VERSION ""

NS_ :

BS_:

BU_: DLCM EPS ESC GWM RCU TCM

BO_ 82 ParkingBrake_0x052: 8 DLCM
 SG_ ParkingBrake : 2|1@0+ (1,0) [0|1] "" Vector__XXX

BO_ 128 EPS_SteeringAngle: 8 EPS
 SG_ SteeringAngle : 23|16@0+ (0.1,-2000.0) [-540|540] "deg" DLCM
 SG_ CRC8 : 63|8@0+ (1,0) [0|255] "" Vector__XXX

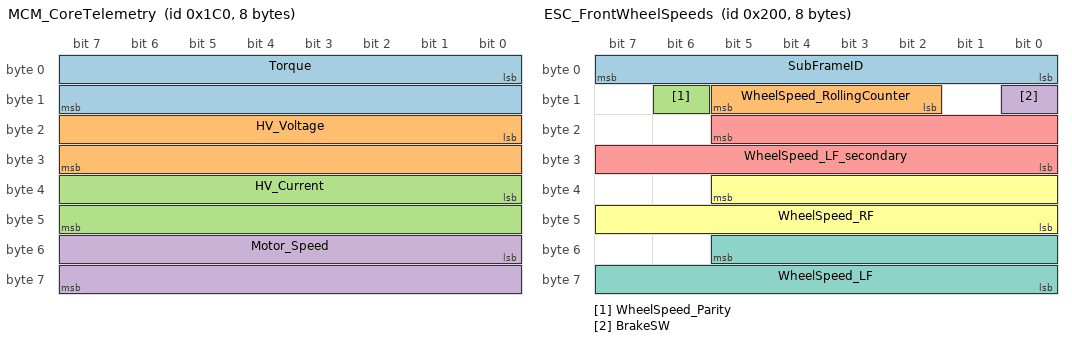
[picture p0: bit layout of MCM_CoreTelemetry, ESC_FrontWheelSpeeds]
BO_ 448 MCM_CoreTelemetry: 8 DLCM
 SG_ Torque      : 0|16@1+  (0.1,-3212.8)  [-500|500]     "Nm"  Vector__XXX
 SG_ HV_Voltage  : 16|16@1+ (0.1,-3212.8)  [0|500]        "V"   Vector__XXX
 SG_ HV_Current  : 32|16@1+ (0.1,-3212.8)  [-500|500]     "A"   Vector__XXX
 SG_ Motor_Speed : 48|16@1+ (0.5,-16064.0) [-12000|12000] "rpm" Vector__XXX

BO_ 512 ESC_FrontWheelSpeeds: 8 ESC
 SG_ SubFrameID              :  7|8@0+ (1,0)  [0|255]   "" Vector__XXX
 SG_ WheelSpeed_RollingCounter : 13|4@0+ (1,0)  [0|15]    "" DLCM
 SG_ WheelSpeed_Parity       : 14|1@0+ (1,0)  [0|1]     "" Vector__XXX
 SG_ BrakeSW                 :  8|1@0+ (1,0)  [0|1]     "" Vector__XXX
 SG_ WheelSpeed_LF_secondary : 21|14@0+ (1,0) [0|16383] "" DLCM
 SG_ WheelSpeed_RF           : 37|14@0+ (1,0) [0|16383] "" DLCM
 SG_ WheelSpeed_LF           : 53|14@0+ (1,0) [0|16383] "" Vector__XXX

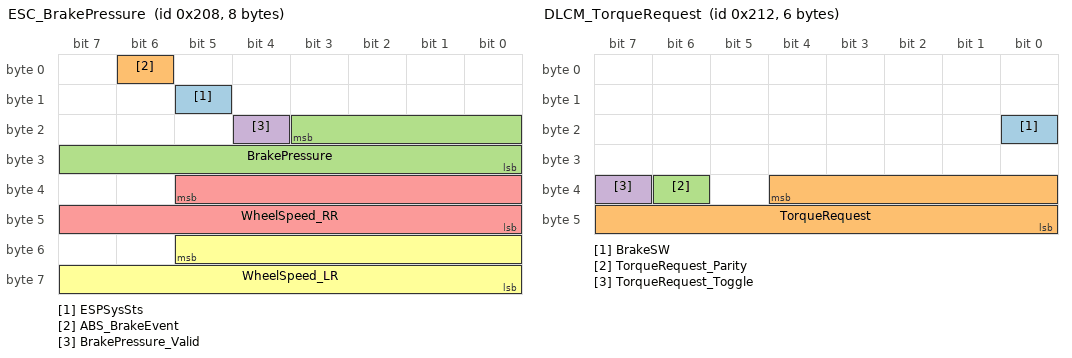
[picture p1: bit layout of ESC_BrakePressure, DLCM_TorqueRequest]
BO_ 520 ESC_BrakePressure: 8 ESC
 SG_ ESPSysSts : 13|1@0+ (1,0) [0|1] "" DLCM
 SG_ ABS_BrakeEvent : 6|1@0+ (1,0) [0|1] "" DLCM
 SG_ BrakePressure : 19|12@0+ (1,0) [0|4095] "" DLCM
 SG_ BrakePressure_Valid : 20|1@0+ (1,0) [0|1] "" DLCM
 SG_ WheelSpeed_RR : 37|14@0+ (1,0) [0|16383] "" Vector__XXX
 SG_ WheelSpeed_LR : 53|14@0+ (1,0) [0|16383] "" Vector__XXX

BO_ 528 VehicleMode_0x210: 6 DLCM
 SG_ ThottlePedalPos : 23|8@0+ (0.4,0) [0|99.6] "%" DLCM

BO_ 530 DLCM_TorqueRequest: 6 DLCM
 SG_ BrakeSW  : 16|1@0+ (1,0) [0|1]   "" Vector__XXX
 SG_ TorqueRequest : 36|13@0+ (0.25,-500) [-500|548.75] "Nm" Vector__XXX
 SG_ TorqueRequest_Parity : 38|1@0+ (1,0) [0|1] "" Vector__XXX
 SG_ TorqueRequest_Toggle : 39|1@0+ (1,0) [0|1] "" Vector__XXX

BO_ 533 misc_0x215: 7 Vector__XXX
 SG_ VehicleSpeed : 7|16@0+ (0.0078125,0) [0|511.9921875] "km/h" Vector__XXX

BO_ 576 SystemState_0x240: 8 Vector__XXX

BO_ 584 ExteriorLights_0x248: 8 Vector__XXX

BO_ 577 MCM_Thermal: 8 DLCM

BO_ 625 misc_0x271: 8 Vector__XXX

BO_ 632 DLCM_DriveKeepalive: 8 DLCM

BO_ 776 DLCM_ParkRequest: 5 DLCM
 SG_ ParkRequest     : 5|2@1+ (1,0) [0|3] "" TCM
 SG_ InputShaftSpeed : 8|16@1+ (0.5,-16064.0) [-12000|12000] "rpm" TCM

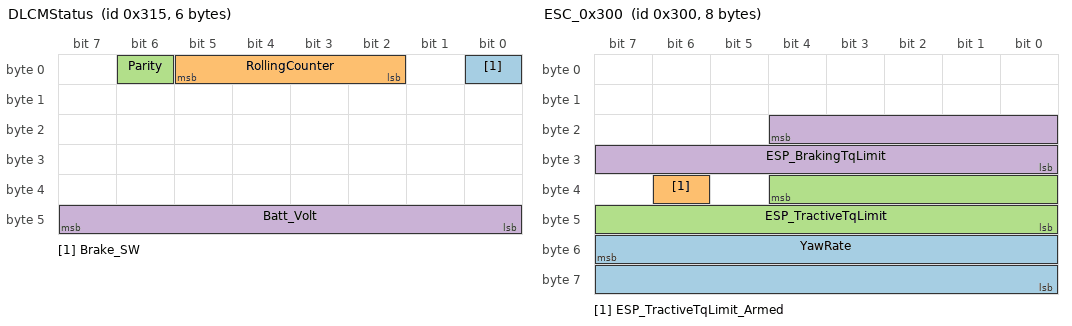
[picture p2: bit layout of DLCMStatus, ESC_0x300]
BO_ 789 DLCMStatus: 6 DLCM
 SG_ Brake_SW : 0|1@0+ (1,0) [0|1] "" Vector__XXX
 SG_ RollingCounter : 5|4@0+ (1,0) [0|15] "" Vector__XXX
 SG_ Parity : 6|1@0+ (1,0) [0|1] "" Vector__XXX
 SG_ Batt_Volt : 47|8@0+ (0.1,0) [0|25.5] "V" Vector__XXX

BO_ 805 DCANAnchor_0x325: 4 Vector__XXX

BO_ 768 ESC_0x300: 8 ESC
 SG_ YawRate : 55|16@0+ (0.0094,-308.2448) [-60|60] "deg/s" DLCM
 SG_ ESP_TractiveTqLimit_Armed : 38|1@0+ (1,0) [0|1] "" DLCM
 SG_ ESP_TractiveTqLimit : 36|13@0+ (2.5,-5000) [-5000|3237] "" DLCM
 SG_ ESP_BrakingTqLimit : 20|13@0+ (2.5,-5000) [-5000|3237] "" DLCM

BO_ 816 misc_0x330: 8 Vector__XXX
 SG_ Long_Accel : 63|8@0+ (0.08,-9.84) [-9.84|10.56] "m/s2" Vector__XXX

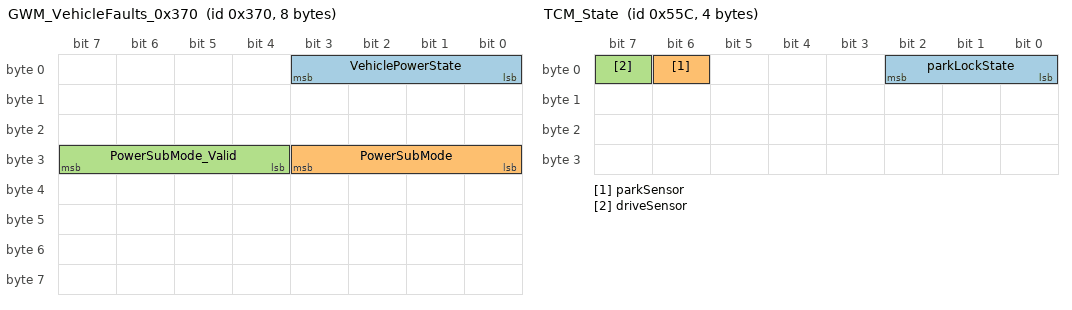
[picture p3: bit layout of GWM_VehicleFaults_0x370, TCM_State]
BO_ 880 GWM_VehicleFaults_0x370: 8 GWM
 SG_ VehiclePowerState  :  3|4@0+ (1,0) [0|15] "" Vector__XXX
 SG_ PowerSubMode       : 27|4@0+ (1,0) [0|15] "" Vector__XXX
 SG_ PowerSubMode_Valid : 31|4@0+ (1,0) [0|15] "" Vector__XXX

BO_ 1048 DLCM_Globals_0x418: 6 DLCM
 SG_ PRND : 7|8@0+ (1,0) [0|255] "" Vector__XXX
 SG_ GearStatus : 39|8@0+ (1,0) [0|255] "" Vector__XXX

BO_ 1372 TCM_State: 4 TCM
 SG_ parkLockState : 0|3@1+ (1,0) [0|6] "" DLCM
 SG_ parkSensor : 6|1@1+ (1,0) [0|1] "" Vector__XXX
 SG_ driveSensor : 7|1@1+ (1,0) [0|1] "" Vector__XXX

BO_ 1408 DCANAnchor_0x580: 4 Vector__XXX

BO_ 1536 misc_0x600: 8 RCU
 SG_ TPMS_TelltaleFault : 61|1@0+ (1,0) [0|1] "" Vector__XXX

BO_ 1786 GWM_VIN: 8 GWM
 SG_ VIN_Frame M  : 7|8@0+  (1,0) [0|2]    "" Vector__XXX
 SG_ VIN_C01  m0  : 15|8@0+ (1,0) [32|127] "" Vector__XXX
 SG_ VIN_C02  m0  : 23|8@0+ (1,0) [32|127] "" Vector__XXX
 SG_ VIN_C03  m0  : 31|8@0+ (1,0) [32|127] "" Vector__XXX
 SG_ VIN_C04  m0  : 39|8@0+ (1,0) [32|127] "" Vector__XXX
 SG_ VIN_C05  m0  : 47|8@0+ (1,0) [32|127] "" Vector__XXX
 SG_ VIN_C06  m0  : 55|8@0+ (1,0) [32|127] "" Vector__XXX
 SG_ VIN_C07  m0  : 63|8@0+ (1,0) [32|127] "" Vector__XXX
 SG_ VIN_C08  m1  : 15|8@0+ (1,0) [32|127] "" Vector__XXX
 SG_ VIN_C09  m1  : 23|8@0+ (1,0) [32|127] "" Vector__XXX
 SG_ VIN_C10  m1  : 31|8@0+ (1,0) [32|127] "" Vector__XXX
 SG_ VIN_C11  m1  : 39|8@0+ (1,0) [32|127] "" Vector__XXX
 SG_ VIN_C12  m1  : 47|8@0+ (1,0) [32|127] "" Vector__XXX
 SG_ VIN_C13  m1  : 55|8@0+ (1,0) [32|127] "" Vector__XXX
 SG_ VIN_C14  m1  : 63|8@0+ (1,0) [32|127] "" Vector__XXX
 SG_ VIN_C15  m2  : 15|8@0+ (1,0) [32|127] "" Vector__XXX
 SG_ VIN_C16  m2  : 23|8@0+ (1,0) [32|127] "" Vector__XXX
 SG_ VIN_C17  m2  : 31|8@0+ (1,0) [32|127] "" Vector__XXX

BO_ 81 misc_0x051: 8 Vector__XXX

BO_ 140 DLCM_0x08C: 1 DLCM
 SG_ Flag_B0bit2 : 2|1@0+ (1,0) [0|1] "" Vector__XXX

BO_ 360 Immobiliser_0x168: 8 Vector__XXX

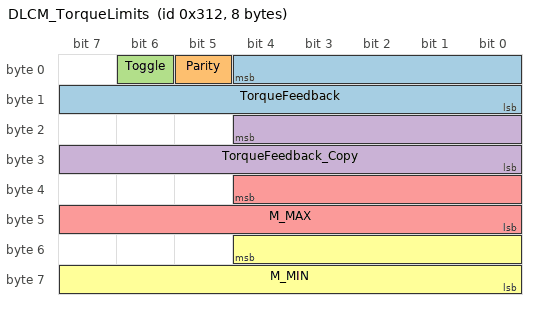
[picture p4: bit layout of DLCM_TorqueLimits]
BO_ 786 DLCM_TorqueLimits: 8 DLCM
 SG_ TorqueFeedback : 4|13@0+ (0.25,-500) [-500|548.75] "Nm" Vector__XXX
 SG_ Parity : 5|1@0+ (1,0) [0|1] "" Vector__XXX
 SG_ Toggle : 6|1@0+ (1,0) [0|1] "" Vector__XXX
 SG_ TorqueFeedback_Copy : 20|13@0+ (0.25,-500) [-500|548.75] "Nm" Vector__XXX
 SG_ M_MAX : 36|13@0+ (0.25,-500) [-500|548.75] "Nm" Vector__XXX
 SG_ M_MIN : 52|13@0+ (0.25,-500) [-500|548.75] "Nm" Vector__XXX

BO_ 1425 DLCM_ImmoVerdict: 7 DLCM
 SG_ Verdict : 7|8@0+ (1,0) [0|255] "" RCU

BO_ 1426 DLCM_ImmoChallenge: 8 DLCM

BO_ 1427 Immobiliser_0x593: 8 Vector__XXX

BO_ 1429 DLCM_0x595: 8 DLCM

BO_ 1539 RCU_ImmoCommand: 7 RCU
 SG_ Step : 7|8@0+ (1,0) [0|255] "" DLCM

BO_ 1556 RCU_ImmoResponse: 8 RCU

CM_ BO_ 82 "Parking brake. Transmitted by the DLCM: TX record 3 in the firmware's CAN configuration table at 0x80041B74, 50 ms period, matching the measured 20.0 Hz. Previously attributed to Vector__XXX. B0 carries six booleans ORed together by FUN_80080C14; only bit 2 (ParkingBrake) is identified.";
CM_ BO_ 128 "Steering angle sensor, factory name EPS SAM_1 (CODACAN), whose field list is Relative Steering angle, EPAS Failure, S/W Calibrated, S/W Sensor Type, Steering Msg Number, crcCheck. EPS transmits on D CAN; the gateway rebroadcasts it byte-exact onto B CAN. Byte map over 20.46 M frames (2026-09-27): B0, B1, B4 always 0x00; B5 0x80 except 38,066 frames at 0x90 (bit 4, meaning unknown, only ever set below 3.3 km/h); B6 message counter (steps +1 and +2); B7 CRC8-J1850. B5 bit 7 is set from the first frame after power-up in every capture, so no bit here marks a change to a calibrated or absolute angle; which bit carries which CODACAN field is not established. See notes/driver-inputs.md.";
CM_ SG_ 128 SteeringAngle "RELATIVE angle, zeroed at EPS power-up: raw 20000 is the wheel position when the EPS booted, NOT straight-ahead. It reads straight-ahead only if the wheel was straight at power-up; park with the wheel turned and straight-ahead reads 20000 minus that turn. Confirmed 2026-09-27 across 869 captures: all 12 EPS restarts resume with the B6 counter at 1 and raw exactly 20000, and the next drive's straight-ahead is predicted by 20000 - (angle at shutdown - previous straight-ahead) to within 5 deg in 96 % of 102 power cycles. Per-drive straight-ahead spans more than a full turn (raw ~14900..25500), and only ~12 % of drives fall within 2 deg of 20000, so a consumer needing straight-ahead must estimate it per power cycle. No re-zero while driving was found, and no absolute steering source is broadcast on any captured bus. The previous comment called 20000 the centre, measured as the corpus median; that median is a statistic of how the car is usually parked, not a property of the signal. STOPS: straight-ahead +/-5710 raw (+/-571 deg) wherever straight-ahead falls; corpus raw range 10281-31119, no saturation, no wrap, and 36 captures exceed the [-540|540] range declared here. SCALE 0.1 deg/count is the factory CODACAN scaling, not physically measured: a stationary lock-to-lock sweep spans 11,314 raw = 3.14 turns at that scale. The offset was -200.0 until 2026-09-20, which put 20000 at 1800 deg; notes/traction-control-analysis.md carried the same 10x error. See notes/driver-inputs.md, Relative angle, zeroed at EPS power-up.";
CM_ BO_ 448 "MCM telemetry forwarded by DLCM from private Motor CAN sub-bus. The M_CAN source is 0x209 (10 ms, 8 bytes, four little-endian uint16 accessors -- the same shape as this message), the MCM spec's AccurateFeedbacks. The DLCM has no COM transmit record for 0x1C0: it is relayed through a hardware mailbox, which is why earlier scans for a transmit site found nothing.";
CM_ SG_ 448 Torque "Regen shows negative values.";
CM_ SG_ 448 HV_Voltage "~335V at mid-SoC LFP pack.";
CM_ SG_ 448 HV_Current "Positive=discharge.";
CM_ SG_ 448 Motor_Speed "Positive=forward.";
CM_ BO_ 512 "ESC front wheel speed message, 200 Hz. NOT MULTIPLEXED -- the M/m0 declaration was removed 2026-09-27; see CM_ SG_ 512 SubFrameID for why and for the sub-frame values that actually occur. This sentence previously described the message as multiplexed and listed 0x0A/0x0B as startup frames, which contradicted both the new structure and the SG_ comment that had already withdrawn 0x0A/0x0B as C CAN values wrongly imported from the message sharing this ID on the other bus. Caught by a peer session, 2026-09-27. CONSUMER OBLIGATION CREATED BY THE DE-MUX: decode() now returns wheel speeds for EVERY sub-frame, including the 0x14 fault state and the 0x1C/0x1E init frames, from the same payload and with no indication that the frame is not a normal one. Before, a consumer that forgot to check SubFrameID got a DecodeError. That loud failure has been traded for a silent one. The trade is deliberate -- the old behaviour made the wheel-speed-fault car decode to SubFrameID alone for all 24,294 of its frames, which is indistinguishable from no data, and that is worse -- but it means EVERY consumer must now gate on SubFrameID itself rather than relying on cantools to refuse. Zero encoding 0xC000. Scale 0.0567 km/h per count (17.61 counts per km/h), equivalently 2.000 counts per wheel rpm -- the same encoding as 0x1C0 Motor_Speed and 0x308 InputShaftSpeed. Measured against 0x491 Primary_ODO, whose 0.1 km/count is verified across three Codas; see notes/artifacts/vehicle_speed_chain.py. CORRECTION 2026-09-24: the wheel speed channels are 14-bit, not 16-bit, and byte 1 is not an 8-bit counter. Layout read out of the DLCM firmware (TriCore image coda_dlcm_prog.bin): every received payload is fetched into a per-message RAM buffer and read only through the accessor band 0x800803FA-0x80080B4A, so the masks there are the module's own view of the field. See notes/dlcm/coda-dlcm-decompile-notes.md and notes/dlcm/artifacts/dlcm_signal_map.py. FUN_800805C2 reads B2 masked 0x3F with B3 and FUN_800805D8 reads B4 masked 0x3F with B5; bits 7-6 of B2, B4 and B6 are 0b11 in 196,707 of 196,707 m0 frames of frombonnydoon.log, which is exactly where the 'zero encoding 0xC000' above comes from -- those two bits are not magnitude. Narrowing the signals to 14 bits moves every decoded value down by 49152; the scale is unchanged. Byte 1 is BrakeSW at bit 0 (99.94 % agreement with 0x315 Brake_SW over 68,688 frames), a 4-bit rolling counter at bits 5-2 (+1 steps in 68,687 of 68,687), parity over (B1 & 0x3F) at bit 6 (68,688 of 68,688), and bits 7 and 1 always zero. The firmware reads only the counter nibble. The DLCM does not read B6-B7 (WheelSpeed_LF) at all.";
CM_ SG_ 512 SubFrameID "B0 sub-frame selector. REWRITTEN 2026-09-26. Values that actually occur on the ESC bus: 0x1E and 0x1C (a fixed startup pair), then 0x00 or 0x14 as the steady state, plus 0x20 in bursts. STARTUP: 0x1E for 1.91 s then 0x1C for 1.99 s, then steady state -- same durations to 10 ms and the same per-channel counts (192 and 200) on two different cars a year apart, so it is a fixed ESC init, not a fault. STEADY STATE selects by fault: a healthy car goes to 0x00, the wheel-speed-fault car goes to 0x14 and never emits 0x00 at all. 0x14 occurs in exactly one file corpus-wide. 0x20 CONFIRMED as a TC-event burst: 150 frames over 1.49 s per bus, appearing as ~300 corpus-wide because the gateway rebroadcast doubles it. Both channels carry it at identical timestamps. ESTABLISHED 2026-09-26 by a fixed-string scan of all 1,102 corpus files in both log roots (notes/artifacts/tpms_tc_event_exposure.py): a burst appears in 15 files / 15 distinct sessions, 16 bursts, 24.3 s of traction control across 221 days, and coda_20260422_102839_T0.log carries TWO bursts (99 s and 266 s in). So 'one block per capture' is NOT a rule and must not be relied on; the earlier 'NOT established' on this point is now answered. Bursts fall at scattered offsets (28 s to 1879 s into a file), so they are driving events and not an init artefact like the 0x1C/0x1E pair; under the 14-bit decode its speed fields are not empty but carry 144-146 distinct values with maxima around 600 against ~1700 for 0x00, so 'content unknown' understates it and the content is still unidentified. 0x0A/0x0B ARE WRONG and are withdrawn: a sweep of 1,082 corpus files found them only on the C CAN message that shares ID 0x200, never on the bus carrying 0x212. That other message has its own B0 spanning roughly 0x07-0x1B plus 0x9C, which also overlaps 0x1C and 0x1E in two files -- so split buses by CONTENT before histogramming B0 here, or you will re-import C CAN values into this comment as someone did in 2026-03. DECODING HAZARD: 0x1C and 0x1E are not declared multiplexer values, so cantools RAISES DecodeError on them ('expected multiplexer id 0, 10, 11, 20 or 32, but got 28' / '30') on every capture containing ESC startup; and because the wheel speeds are gated m0, the fault car decodes to SubFrameID alone with NO wheel speeds for all 24,294 of its frames, which is indistinguishable from no data. FIRMWARE: the DLCM does NOT gate on this byte. It copies every 0x200 frame into one buffer and reads the wheel-speed fields unconditionally; the only part of B0 read anywhere is bit 2 (FUN_800805EE), which feeds a status boolean and the safety monitor, not a demux. So the firmware CANNOT corroborate '0x14 has the same layout as 0x00' -- it never looks, and its silence must not be read as confirmation. That claim rests on log data alone. STARTUP POSITION, 2026-09-27: the 0x1E/0x1C pair marks a key-on, so it appears wherever in a capture the key-on falls -- including mid-capture when the key is cycled -- and its position in the file says nothing about the file. Confirmed by 23 mid-capture key cycles across 19 captures, each dated independently by 0x370 VehiclePowerState; see notes/key-cycle-detection.md. MULTIPLEXER REMOVED 2026-09-27. SubFrameID was declared M with every other signal gated m0. That was wrong in three ways and actively destructive: 0x1C and 0x1E were not declared mux values so cantools raised DecodeError on every capture containing ESC startup; the wheel-speed-fault car emits 0x14 for all 24,294 of its frames and so decoded to SubFrameID alone with NO wheel speeds, which is indistinguishable from no data; and the DLCM itself does not demux, as described above. All signals are now ungated. Verified on coda_20260322_153141_T0: 28,817 frames at 0x00, 200 at 0x1C and 192 at 0x1E all decode, all carrying wheel speeds, zero errors. B0 BIT 2 IS NOT AN INDEPENDENT BIT and is deliberately not declared as a signal: across the full observed value set it is set for 0x14, 0x1C and 0x1E and clear for 0x00 and 0x20, i.e. it is a function of SubFrameID meaning 'not a plain wheel-speed frame', covering both the fault steady state and the two init values. It is the only part of this byte the firmware reads. VAL_ CORRECTED 2026-09-27: 10 'Startup_0x0A' and 11 'Startup_0x0B' removed -- they were withdrawn in the prose above as C CAN values wrongly imported here, but had been left in the value table, which contradicted the comment. 0x1C and 0x1E added. See notes/artifacts/handoff_0x200_subframeid.md and notes/dlcm/coda-dlcm-decompile-notes.md.";
CM_ SG_ 512 WheelSpeed_RollingCounter "B1 rolling counter 0-125, valid only in SubFrameID=0x00 sub-frames.";
CM_ SG_ 512 WheelSpeed_LF "Zero=0xC000. Valid only in SubFrameID=0x00. Outer wheel in right turns. Spikes during FWD TC events. Scale 0.0567 km/h per count (17.61 counts per km/h), equivalently 2.000 counts per wheel rpm -- the same encoding as 0x1C0 Motor_Speed and 0x308 InputShaftSpeed. Measured against 0x491 Primary_ODO, whose 0.1 km/count is verified across three Codas; see notes/artifacts/vehicle_speed_chain.py. LOW-SPEED FLOOR (measured 2026-10-15, notes/dlcm/artifacts/chock_impact_check.py phases 2-3): this field reads 0 below ~15.5 wheel rpm, twice the 8.0 rpm floor of WheelSpeed_LF_secondary, RF, LR and RR; no non-zero value below 15.5 rpm occurs. LF_secondary, the same physical sensor, keeps the 8.0 rpm floor, so the difference is in how the ESC fills this field, not in the sensor. At all 395 braked stops sampled on this car this field was the first wheel to read 0, 0.18 / 0.28 / 0.57 s (p10 / p50 / p90) before the next. The parts car shows the same split (codapartscarlog.log). Consequence: an early zero here is NOT evidence of an impact or lock-up; use WheelSpeed_LF_secondary for low-speed work, and see its comment on the naming.";
CM_ SG_ 512 WheelSpeed_RF "Zero=0xC000. Valid only in SubFrameID=0x00. Inner wheel in right turns. Spikes during FWD TC events. Scale 0.0567 km/h per count (17.61 counts per km/h), equivalently 2.000 counts per wheel rpm -- the same encoding as 0x1C0 Motor_Speed and 0x308 InputShaftSpeed. Measured against 0x491 Primary_ODO, whose 0.1 km/count is verified across three Codas; see notes/artifacts/vehicle_speed_chain.py.";
CM_ SG_ 512 WheelSpeed_LF_secondary "Same physical sensor as WheelSpeed_LF (B6-B7), but NOT identical to it -- 'identical' corrected 2026-09-26. Measured on frombonnydoon, SubFrameID=0, n~196,700 per channel: byte-identical on only 45.7 % of frames, standard deviation of the difference 1.9 counts, and 3.81 % differ by more than 2. 'Same physical sensor' survives easily -- 1.9 counts against a signal spanning more than 1000, with near-zero mean offset. A whole-frame lag is excluded: same-frame matching (45.7 %) beats both one-frame shifts (22.1 % and 28.7 %). The disagreement is flat in speed (correlation +0.08, invariant) and positive against acceleration under every derivative estimator tried, but the magnitude is estimator-dependent and should not be quoted as a point value. Below 50 counts the channels agree 92.8 % of the time, with a heavy tail. Both channels give identical statistics on either bus, which also establishes that the gateway rebroadcast of 0x200 is byte-exact. DESPITE THE NAME, this is the left-front channel to prefer (2026-10-15): the DLCM reads this field and B4-B5 RF, not B6-B7 WheelSpeed_LF (coda-dlcm-decompile-notes.md), and its zero-speed floor is 8.0 wheel rpm like RF, LR and RR on this car and the parts car, where WheelSpeed_LF's is 15.5 rpm (notes/dlcm/artifacts/chock_impact_check.py phase 3). The primary/secondary labels date from traction-control-analysis.md (2026-03) and rest on no evidence; they are kept so InfluxDB field names and existing scripts do not change.";
CM_ BO_ 520 "ESC module. B4-B5=WheelSpeed_RR, B6-B7=WheelSpeed_LR (corrected from prior FL/FR hypothesis). CORRECTION 2026-09-24: BrakePressure is a 12-bit value with a separate validity bit, not a 16-bit field. Layout read out of the DLCM firmware (TriCore image coda_dlcm_prog.bin): every received payload is fetched into a per-message RAM buffer and read only through the accessor band 0x800803FA-0x80080B4A, so the masks there are the module's own view of the field. See notes/dlcm/coda-dlcm-decompile-notes.md and notes/dlcm/artifacts/dlcm_signal_map.py. FUN_8008062E computes ((B2 << 8) & 0xF00) | B3 and FUN_8008061C returns (B2 & 0x10) >> 4; both are called from the same two consumers, so no code in the image reads the magnitude without the flag. The old (1,-4096) offset happened to give the right number only because bit 12 IS the validity bit and is set whenever the signal is valid; invalid frames decoded as -1. B2 bits 7-5 are never set in any frame. The rear wheel speeds are narrowed to 14 bits on the same basis as 0x200, but by wire evidence only (B4 and B6 bits 7-6 are 0b11 in 197,248 of 197,248 frames) -- the DLCM does not read them, so there is no firmware confirmation. The firmware DOES read B0 bit 6, which no signal here covers; and it does NOT read ESPSysSts, which is set in 197,078 of those frames. **B0 BIT 6 IDENTIFIED 2026-10-03: it is the ABS BRAKE EVENT line, named by the DLCM's own DTC table.** Accessor FUN_8008060E (a0-0x1060 & 0x40 >> 6) -> FUN_8006ED3C, which stores a raw copy at a0-0x27d8 and a validity-qualified copy at 0xD000682E, and runs a rationality counter against CAL 0xA00212BE = 6000 feeding DEM event 124 = U2111 'Invalid Anti Lock Braking System Brake Event' (the neighbouring bit via FUN_800805EE feeds event 123 = U2110 'Invalid Anti-Lock Braking System Lamp Request'). The 'is 0 in every frame observed' clause above was true of the captures then to hand and is now known to be a property of the population, not of the signal: it asserts for 98 frames / 0.97 s in coda_20261002_175334 at t=424.02, 40 ms after a front-wheel slip and 40 ms before a full regen cut, and is 0 across 650,000+ frames of six other sessions. Its one consumer in the image is FUN_800764F6, which forces that function's output to zero when this bit and the commanded brake-lamp state 0xD0006831 are both set. See notes/dlcm/esp-torque-intervention.md.";
CM_ SG_ 520 BrakePressure "Engages ~40ms after brake switch.";
CM_ SG_ 520 ESPSysSts "B1 bit 5. Active (0x20) when ESC on, 0x00 at key-off.";
CM_ SG_ 520 WheelSpeed_RR "Zero=0xC000. Non-driven axle (does not spike during FWD TC events). C102B DTC 'Right Rear Wheel Speed Sensor Circuit' -- parts car confirms by stuck-at-0xFFFF fault sentinel. Scale 0.0567 km/h per count (17.61 counts per km/h), equivalently 2.000 counts per wheel rpm -- the same encoding as 0x1C0 Motor_Speed and 0x308 InputShaftSpeed. Measured against 0x491 Primary_ODO, whose 0.1 km/count is verified across three Codas; see notes/artifacts/vehicle_speed_chain.py.";
CM_ SG_ 520 WheelSpeed_LR "Zero=0xC000. Non-driven axle. Tracks vehicle reference speed. Scale 0.0567 km/h per count (17.61 counts per km/h), equivalently 2.000 counts per wheel rpm -- the same encoding as 0x1C0 Motor_Speed and 0x308 InputShaftSpeed. Measured against 0x491 Primary_ODO, whose 0.1 km/count is verified across three Codas; see notes/artifacts/vehicle_speed_chain.py.";
CM_ BO_ 528 "Vehicle mode / throttle. 50 Hz. Transmitted by the DLCM: TX record 7, 20 ms period. Previously attributed to Vector__XXX. Firmware also writes B3 bit 7 (parity over B2) and B4 bit 7 (alternating toggle), neither yet declared as a signal.";
CM_ BO_ 530 "DLCM Torque Request message (NOT steering angle -- VICD originally tagged EPS_SAM_1). 50 Hz. CORRECTION 2026-09-24: it is NOT two alternating sub-frames at 25 Hz. There is one TX record and one signal record; B2 bit 3 and B4 bit 7 are alternating toggle bits (50.00 % over 98,597 frames) and B2 bit 2 and B4 bit 6 are parity bits (both 100.00 % against the firmware expressions), which is what the B2 = 0x0C / 0x00 pattern was. Nothing is multiplexed and TorqueRequest is present in every frame. Layout read out of the DLCM firmware (TriCore image coda_dlcm_prog.bin): every received payload is fetched into a per-message RAM buffer and read only through the accessor band 0x800803FA-0x80080B4A, so the masks there are the module's own view of the field. See notes/dlcm/coda-dlcm-decompile-notes.md and notes/dlcm/artifacts/dlcm_signal_map.py. FUN_80080C14 writes the torque at B4 masked 0x1F with B5 from 0xD00069D2, the same variable DID 8539 reads; the encoding is raw = internal * 0.4 + 2000 with internal in 0.1 Nm, i.e. 0.25 Nm/count with zero at 2000. B4 bit 5 is always 1. B2 bits 1-0 come from the same firmware variable as 0x315 B0 bits 1-0.";
CM_ SG_ 530 BrakeSW "Triple-redundancy: same signal at 0x315 B0.bit0 and 0x200 B1.bit0. Confirmed 2026-09-24. The 0x212 and 0x315 copies are not independent -- FUN_80080C14 writes both from one variable (DAT_d00069E0 & 3). 0x200 is an ESC transmission and is the genuinely independent third copy: its B1 bit 0 agrees with 0x315 Brake_SW in 68,648 of 68,688 frames (99.94 %), the mismatches being single-frame edges.";
CM_ BO_ 533 "VICD: misc_Recvd 0x215. B0:B1 = VehicleSpeed (2026-10-26). B2:B3 and B4:B5 track each other while moving but are not wheel speeds; B6 has 4 values; all undecoded. Transmitter not shown: the DLCM receives it; the content is derived from the ESC wheel speeds, so the ESC is suspected. The TCM.ParkLock candidate was invalidated 2026-09-24. DLC corrected 2026-09-24 from 2 to 7: the DLCM's RX record declares 7 and the wire shows DLC 7.";
CM_ SG_ 533 VehicleSpeed "B0:B1 big-endian, km/h x 128. Confirmed 2026-10-26: integrated over time it reproduces the 0x491 odometer distance on four drives (ratio 0.991-1.006), and it correlates r = 1.000 with each ESC wheel speed (0x200/0x208) at a constant ratio. Zero whenever stationary. The HVAC reads it with a precedence bug. See notes/hvac/coda-hvac-decompile-notes.md section 5.4.";
CM_ BO_ 576 "System power mode. B0: 0x11=key-on (HV off), 0x01=Ready (HV on). Medium confidence. D+B CAN (gateway rebroadcast). DLC unconfirmed. See notes/driver-inputs.md.";
CM_ BO_ 584 "Exterior lights state. B1.bit3=any exterior lights on (boolean). B6=possible instrument dimming (unconfirmed). Medium confidence. D+B CAN (gateway rebroadcast). DLC unconfirmed. See notes/driver-inputs.md.";
CM_ BO_ 577 "MCM motor thermal data relayed by DLCM from private Motor CAN sub-bus. Carries Rotor temp, Stator temp, IGBT temp per CODACAN DLCM tab. Encoding: probable offset -40 degC, per-byte assignment unconfirmed. NOTE: 8 bytes seen in log data -- DLC may be higher than 3, verify before use. The M_CAN source is 0x20E (100 ms, exactly three byte-wide accessors in the firmware, matching the rotor/stator/IGBT triple), the MCM spec's Temperature message. Like 0x1C0 this is relayed through a hardware mailbox with no COM transmit record.";
CM_ BO_ 625 "VICD: misc_Recvd 0x271. Death Counter partial (integer bytes).";
CM_ BO_ 632 "DLCM Drive Keepalive. Carries KeepWakeNetworkDLCM and EngineStsRun per CODACAN. B1 bit 6 (mask 0x40) = HV/Drive Ready flag (medium confidence). Signal byte positions unconfirmed. DLC corrected 2026-09-24 from 2 to 8: the DLCM's TX record declares 8 and the wire shows DLC 8. Firmware writes only B0 and B1 bit 6, which matches the HV/Drive Ready note above.";
CM_ BO_ 776 "Park request from the DLCM to the BorgWarner TCM, plus the shaft speed the DLCM sends it. 10 ms, D CAN exclusive. B3-B4=constant 0x00. InputShaftSpeed uses the same encoding as Motor_Speed (0x1C0 B6-B7). CORRECTED 2026-09-24 -- this is NOT a TCM broadcast and B0 is NOT a pin-state report. It is TX record 9 in the DLCM's own CAN transmit table at 0x80041B74 with a 10 ms period, matching the measured 99.7 Hz, and FUN_80080C14 assembles all five bytes, taking B1-B2 from 0xD00069CA. ADDED 2026-10-06: 0xD00069CA = 0xD0005114 + 0x7D80, written by FUN_80074780 (search limited to the exported function set). The Vtrux EPRI DBC independently calls the same id the HCU park request command. Direction settled from data on both vehicles: the B0 change LEADS the TCM's own 0x55C parkLockState in both directions -- Coda +76, +89, +88, +85 ms over two P-R-N-D-N-R-P cycles; Vtrux +55 and +65 ms -- which a pin-state report cannot do on park ENGAGE. The 55-65 ms figures already recorded in notes/borgwarner.md as solenoid actuation delay are that command-to-acknowledge latency. The TCM's own state feedback is 0x55C. See notes/borgwarner.md.";
CM_ SG_ 776 ParkRequest "Byte 0 bits 6-5, a 2-bit command: 0=OFF, 1=Park, 2=UnPark. Bit spec and value table taken verbatim from the Vtrux EPRI DBC (SG_ ParkRequest : 5|2@1+ in epri-pt-bus.dbc, decoded from the vendor logging app), and matched exactly by the Coda firmware, which ORs DAT_d0006AF1 * 0x20 & 0x60 into this byte. Was declared as an 8-bit ParkPinState with 32=Park / 64=NotPark; those are the same two values seen as a 2-bit field (0x20 = 1, 0x40 = 2), but the third state 0 = OFF was missing and no bit outside 6-5 is ever set (0 frames of 3,855 on Coda, 0 of 6,423 on Vtrux).";
CM_ SG_ 776 InputShaftSpeed "Zero=0x7D80. Input shaft (not output): ratio to motor RPM = 2.000 on both Vtrux and Coda regardless of gear ratio.";
CM_ BO_ 789 "DLCM status. B1,B3 zero when stationary. CORRECTION 2026-09-24: B0 bits 7-2 are NOT a 6-bit rolling counter. Layout read out of the DLCM firmware (TriCore image coda_dlcm_prog.bin): every received payload is fetched into a per-message RAM buffer and read only through the accessor band 0x800803FA-0x80080B4A, so the masks there are the module's own view of the field. See notes/dlcm/coda-dlcm-decompile-notes.md and notes/dlcm/artifacts/dlcm_signal_map.py. FUN_80080C14 writes the counter as DAT_d0007F7E * 4 & 0x3C -- four bits at 5-2 -- and puts parity over (B0 & 0x3F) at bit 6. Measured on 98,597 frames: bits 5-2 advance by +1 in 98,596 of 98,596 steps (100.00 %), the old 6-bit reading only 31.27 %, and the parity holds in 98,597 of 98,597. Bit 7 and bit 1 are always zero; bit 0 is Brake_SW. This is the same defect shape as 0x200 byte 1.";
CM_ SG_ 789 Brake_SW "Engages ~40ms before hydraulic pressure.";
CM_ SG_ 789 Batt_Volt "Cross-check vs DCDC 14VMonitor (0x1D5).";
CM_ BO_ 805 "D CAN exclusive anchor ID. Never rebroadcast to B CAN. Signal content unknown.";
CM_ BO_ 816 "Longitudinal accelerometer, 50 Hz. DLC is 8, not the 1 previously recorded here: B0-B6 are constant (FC FC FC FD FF FF FF) and only B7 carries the signal. The earlier note read B0 as the accelerometer, which is a dead constant of -4. Confirmed 2026-09-20 against wheel-speed-derived acceleration over four drives.";
CM_ SG_ 816 Long_Accel "B7, offset binary with zero at raw 123 (the modal value over a whole drive; a regression against kinematic acceleration puts it at 122.6). Scale 0.08 m/s2/count is from VICD and is corroborated to about +/-12 % by the regression slope across drives, so treat the SCALE as approximate and the zero and the role as confirmed. Raw >= 200 is invalid (about 13 samples per drive) and should be discarded. Correlation against acceleration derived from 0x208 WheelSpeed_LR: r = 0.83-0.89 raw, rising to 0.88-0.93 once road grade is removed with a 30 s high-pass. The residual is dominated by noise in the wheel-speed derivative, not by this signal -- r rises monotonically as the derivative window widens, and is flat across +/-200 ms of lag. Independent physical check: integrating the recovered grade term gives -177 m over the frombonnydoon mountain descent and +6 m / +9 m over flat urban drives, with gradients of +/-9 % and +/-4 % respectively.";
CM_ BO_ 880 "GWM Vehicle Faults. Sender CONFIRMED as the GWM by the factory diagnostic manual: DTC master list row 215, U0146 \"COM Timeout with GWM (Vehicle Faults - 0x370)\" set by the BMU -- the same naming convention as row 214, U0108 \"COM Timeout with CHM (0x615)\", where the named module is the sender. Previously misc_0x370, sender Vector__XXX. VICD called it the Death Counter batch; the DLCM reads seven fields from it into its DTC evaluation block FUN_80074478, so both readings can hold in 8 bytes. ORIGINATES ON B CAN, not D CAN: in codadriveslowturnonwithdefroster2.log and DCDCRUNNingwithoutkeyon-then-key-on.log it is present from +0.01 s with D CAN asleep and reaches D CAN only when D CAN wakes (+9.46 s / +41.88 s); 2836 frames on B against 742 on D. The two copies are NOT identical -- B1 differs in 100 % of 34,919 matched pairs and looks like a bus tag (0x02 on D, 0x06 on B); every other byte including B0 matches exactly, which is what makes B0 usable as a bus-independent witness. The influx_upload coda profile excluded this on b_can until 2026-09-26, which kept the gateway copy and dropped the original; corrected to d_can. FILTER QUERIES TO bus='b_can'. After the 2026-09-27 rebuild InfluxDB holds 281,313 0x370 points on b_can carrying the full state ladder 0,1,2,3,4,5,6,9, plus 19 points spread across c_can, ch1 and ch2 that read only 0 and 1. Those 19 are not this message -- 0x370 is not in the C CAN native set listed in projects/coda/README.md -- and they decode to a spurious 'off'. The contamination is 0.007 % and sits entirely at the off end, so it will not move an aggregate, but a query looking for key-off events without a bus filter will find 19 fictitious ones. Not excluded in the upload profile because doing so costs a full corpus re-upload for 19 points; revisit if 0x370 is ever excluded for another reason. Fields read by the firmware: B0[3:0], B0[6:4], B1 bit 0, B1 bit 1, B1[3:2], B3[3:0], B3[7:4]. B1 and B0[6:4] are not yet declared as signals. Layout read out of the DLCM firmware (TriCore image coda_dlcm_prog.bin): every received payload is fetched into a per-message RAM buffer and read only through the accessor band 0x800803FA-0x80080B4A, so the masks there are the module's own view of the field. VICD additionally described it as a Death Counter batch using 6 bytes (B0-B4, B7) at 0.1 scale; those counters are not decoded here. See notes/dlcm/coda-dlcm-decompile-notes.md, notes/dlcm/artifacts/dlcm_signal_map.py and notes/key-cycle-detection.md.";
CM_ SG_ 880 VehiclePowerState "Vehicle power-state enumeration, and the only key-state indicator found so far that SURVIVES a key-off -- the GWM stays powered, so this dates an ignition cycle from outside it. 0x240 cannot: it reads 0x01 in 11,670 of 11,672 frames and dies with the key. FIELD BOUNDARY CONFIRMED: the DLCM reads B0 masked 0x0F (FUN_80080666) as its own field, and B0's high nibble is a constant 0x1 across 15,000 frames. VALUE NAMES ARE INFERRED from position in the ladder, not documented: the sequence 2 -> 4 -> 9 -> 6 -> 5 on the way up and 5 -> 3 -> 1 on the way down was read off codadriveslowturnonwithdefroster2.log, a deliberate slow key-on, and matches the key positions recorded independently in notes/driving-sequence-investigation.md (2026-02-19) to 0.04 s. The same ladder appears in 23 mid-capture key cycles across 19 captures corpus-wide. NOT the spec's Powermode signal despite covering the same state set: the DLCM functional requirements compare Powermode ordinally (< Ignition_On, < Ready) and these codes are not ordered -- Crank is 9, Ready is 5. Treat it as a coded enum over the Powermode states. A genuine key-off always shows the descent BEFORE the GWM stops; the same value either side of a silence with no descent means the capture lost the bus, not that the key moved. READ THE B CAN COPY FOR A KEY-OFF, NOT THIS ONE (established 2026-09-27 with a peer session, and it corrects the dwell figures first written here). The GWM stops rebroadcasting 0x370 onto D CAN about 6 s into the off period while still transmitting it on B CAN: measured B-minus-D survival of 6.2, 6.2, 6.2 and 6.1 s across four captures. So the D CAN copy TRUNCATES the descent -- it typically ends mid-state-1 and never reaches the terminal state 0 at all, which is why state 0 was initially missed and why state 1 looked like a 1.1 s flicker here when its real dwell on B CAN is 5.2 s (median, n=6). Dwells measured on B CAN: state 3 median 5.0 s but ranging 3.6-12.5 s and observed as long as 56.9 s, so it is NOT a fixed-length transition and something can hold the car there; state 1 median 5.2 s. A short key-off is still fully visible on D CAN but anything longer needs B CAN. THE DESCENT IS TIME-ORDERED and how far it gets depends on how long the key stays off: state 3 takes 5.0 s and state 1 a further ~5.2 s, and a restart resumes from wherever it reached, so BOTH 1 -> 2 and 0 -> 2 ascents are real. A key-off under about ten seconds turns around in state 1 and never reaches 0. coda_20260322_160846_T0 shows both on one channel in one file: a mid-file 8.7 s cycle that turns around at 1, and an end-of-file key-off that runs to 0. Consequently a SHORT STATE-1 DWELL HAS TWO CAUSES and only one is an artefact -- on D CAN the hold-off can cut the state short (the state continued, you stopped seeing it), while on any bus a quick restart can genuinely interrupt it. Tell them apart by what follows: a truncation ends the message, an interruption is followed by 2. STATE 0 IS OBSERVED AND NOW LABELLED (observed 2026-09-27, raised by a peer session; labels approved 2026-09-29). The full descent is 5 -> 3 -> 1 -> 0, not 5 -> 3 -> 1: in coda_20260322_160846_T0 the state reaches 0 at t=128.3 s, about 5 s after state 1, and holds for the remaining 80 frames. It was missed initially because the other two captures end before getting there -- coda_20260322_153141_T0 restarts first, and the slow key-on capture ends 1.3 s after reaching state 1. So 0 is the terminal off state, and the VAL_ table now reads 0 \"Off\" and 1 \"Shutdown\" -- 1 is a timed step above 0 (median dwell 5.2 s on B CAN, n=6), mirroring 2 as the first step up. It previously read 1 \"Off\" with no entry for 0. THE EVIDENCE IS THE DESCENT TIMING, not the shape of the ascent: an earlier justification that 'the ascent leaves from 0' is wrong as a general rule, because the ascent leaves from wherever the descent reached and both 1 -> 2 and 0 -> 2 are real. Names remain INFERRED from position in the ladder, like the rest of this table.";
CM_ SG_ 880 PowerSubMode "Power sub-mode, B3[3:0]. Read by the DLCM (FUN_80080692). Observed 1..4, settling at 4 once HV is up: 0xF1 before wake, 0x11 at wake, 0x12 at crank, 0x14 once precharge completes, reversing 0x14 -> 0x13 -> 0x11 at shutdown. Matches the 0x370 B3 hypothesis in notes/driving-sequence-investigation.md. Value names inferred from ladder position.";
CM_ SG_ 880 PowerSubMode_Valid "B3[7:4], read separately by the DLCM (FUN_800806A2). 0x1 whenever the message is meaningful; 0xF while the module is asleep or the value is not yet valid (seen as B3 = 0xF1 at t=0 before wake, and briefly during a key-off). Reading PowerSubMode without checking this nibble will treat the asleep sentinel as sub-mode 1.";
CM_ BO_ 1048 "DLCM globals. Active in both key-on and Ready states.";
CM_ SG_ 1048 PRND "ASCII-encoded: P=0x50, R=0x52, N=0x4E, D=0x44.";
CM_ SG_ 1048 GearStatus "B4 uint8. P=0xDD, R=0xBB, N=0x00, D=0x11. Intermediate values during shifts. Medium confidence.";
CM_ BO_ 1372 "BorgWarner TCM state heartbeat, transmitted by the TCM. 10 Hz. B1-B3=constant 0x00. CORRECTED 2026-09-26: byte 0 is three fields, not an 8-bit TCMState. It is parkLockState at bits 2-0, parkSensor at bit 6 and driveSensor at bit 7. Three sources agree and the old 8-bit signal was the outlier: the Vtrux EPRI DBC already declared exactly this split (epri-pt-bus.dbc, parkLockState 0|3@1+, parkSensor 6|1@1+, driveSensor 7|1@1+, decoded from the vendor app); notes/borgwarner.md documents the same three fields from cross-vehicle log analysis; and the Coda DLCM firmware reads only bits 2-0 (FUN_80080940 returns (a0-0xff8) & 7). The bit spec here is taken verbatim from the EPRI file for cross-vehicle consistency. The old VAL_ table was the tell: 66, 4, 133, 1 are COMPOSITE byte values, not states -- 66 = 0x42 is state 2 (Parked) plus the parkSensor bit, and 133 = 0x85 is state 5 (Unparked) plus the driveSensor bit. It enumerated four observed combinations of a 3-bit state and two flags, which is why it could not express the other three states. Signal renamed TCMState -> parkLockState to match Vtrux; nothing in the repo referenced the old name outside this file. This is the SECOND id where the EPRI DBC was right and the Coda DBC was wrong on the same message pair -- see 0x308, corrected 2026-09-24. Cross-vehicle: Coda and Vtrux share identical structure.";
CM_ SG_ 1372 TCMState "0x42=Steady Park, 0x04=Park releasing (~55ms after 0x308 pin release), 0x85=Drive/Manual, 0x01=Park engaging (~65ms after pin locks).";
CM_ BO_ 1408 "D CAN exclusive anchor ID. Never rebroadcast to B CAN. Signal meaning still unknown, but the DLCM does consume it: FIRMWARE 2026-09-24 shows seven fields read through the accessor band -- B0 bit 4, bit 5, bit 6 and bit 7 as four separate booleans, B1 bit 6, B1 as a whole byte, and B2 via two accessors. So this is not a pure heartbeat. Layout read out of the DLCM firmware (TriCore image coda_dlcm_prog.bin): every received payload is fetched into a per-message RAM buffer and read only through the accessor band 0x800803FA-0x80080B4A, so the masks there are the module's own view of the field. See notes/dlcm/coda-dlcm-decompile-notes.md and notes/dlcm/artifacts/dlcm_signal_map.py.";
CM_ BO_ 1536 "RCU on D CAN, gateway-rebroadcast byte-identically onto B CAN (1753 vs 1757 frames in one capture) where the IPK reads it -- the RCU is D CAN only (IP89 cav 1/6) and the IPK B CAN only (IP29 cav 1/2), so this frame is the only RCU information reaching the cluster besides the hardwired immobiliser LED (TP09 -> IP29:22). NOT tyre pressure -- the VICD 'TPMS pressure, 1.37 kPa/count' candidate is DISPROVED (2026-09-20). (B6<<8)|B5 is the RCU's AWAKE-TIME counter, little-endian, ~1 count per 1.05 s: 3761 consecutive frames with zero decreases and steps of 0 and 1 only WITHIN a power cycle, but it ZEROES on an RCU restart, so it is not monotonic across one. It counts only while the RCU is awake -- it advanced just ~20 counts across 17 h parked (2026-09-20 17:32 to 2026-09-21 10:58). Useful as a frame-local reset detector: the counter zeroing marks the exact power event, without inferring it from B7 runs. B1=01 B2=01 B3=07 B4=00 are frozen -- verified across all 985 corpus files, not just one drive. B0 cycles a 4-phase tag 00/03/10/13 with IDENTICAL payload in each phase, so it is not a per-wheel multiplexer. A whole-bus sweep found no pressure-shaped channel on any ID. DLC is 8 on the wire, not the 2 previously declared. CORRECTION 2026-09-21: B7 was described here as 'a slow high-order counter byte (0x6A in Feb 2026, 0x4A in Sep)'. It is not a counter -- 0x6A -> 0x4A is a single-bit DECREASE. B7 takes exactly two values corpus-wide, 0x4A and 0x6A, differing only in bit 5 = TPMS_TelltaleFault. See notes/indirect-tpms-feasibility.md section 1.";
CM_ SG_ 1536 TPMS_TelltaleFault "B7 bit5. Consumed by the IPK, which is a B CAN node and so is not in this file's BU_ list -- it sees the frame only via the gateway rebroadcast. 1 = TPMS fault latched, cluster telltale lit; 0 = clear. CONFIRMED 2026-09-21: flipped 0->1 at 11:09:56 in coda_20260921_105818_T2 against the owner's independent observation of the lamp lighting at 11:10. Cleared by an RCU power interruption -- and a BRIEF one suffices: in coda_20260425_222956_T1 at t=59.7 s the bit clears on the same frame as the awake counter zeroing (4130 -> 0) while the 0.524 s transmit cadence never breaks, so the RCU was down for under ~500 ms. Its TPMS fault memory is therefore volatile, weaker than the service manual's 'reset only on a DTC clear or battery disconnect' implies. That chunk contains no diagnostic traffic at all (no 0x700-0x7FF), so it was not a tester DTC clear. No case of the bit self-clearing without the counter zeroing has been seen; re-latches after 421.3 s (7 min) of driving above 30 km/h accumulated since the reset -- sd 1.07 s over six power-event clusters, and both figures appear verbatim in the service manual. Ignition-on time (cv 1.26) and PRND==D (cv 0.25) are ruled out as the trigger. The bit does not toggle, so the flash-then-steady malfunction pattern is generated inside the IPK, not commanded frame-by-frame.";
CM_ BO_ 1786 "GWM rebroadcasts VIN on D CAN (same 0x6FA as B CAN). See B CAN DBC for full encoding.";
CM_ SG_ 1786 VIN_Frame "See B CAN DBC for full char layout.";

CM_ BO_ 81 "Received by the DLCM at 100 ms (RX record 9) and consumed: FUN_800806B4 returns B0, which FUN_80074390 tests for 0x00 or 0x55 and otherwise raises DTC events 0x2D, 0x76 and 0x64. The payload is 00 00 00 00 00 00 00 00 in all 4,374,280 frames across 1,022 corpus captures, so nothing has ever been observed in it. Transmitter unidentified -- nothing in the DLCM image names it.";
CM_ BO_ 140 "Transmitted by the DLCM once per second (TX record 13), DLC 1. The only content is bit 2, written by FUN_800779D8 as a debounce-limited pulse: true while an internal condition holds AND a counter stays under the calibration threshold at 0xA002187A, with a calibration override at 0xA0021882. Corpus-wide the byte is 0x00 in 197,305 frames and 0x04 in exactly two, both in coda_20260715_162457_T0.log about two seconds after that session's 0x591 = 0xB0 verdict. The meaning of the bit is a hypothesis on that single observation, not established.";
CM_ BO_ 360 "Configured as an RX message at 100 ms but never observed: zero frames in 1,030 corpus captures. FUN_80073824 reads B0 bits 1-0 as a command and bytes 5-8 as a 32-bit value, and compares that value against a key derived with 0x9D89EA36 -- the SecurityAccess level-3 constant -- latching the same lockout flag the immobiliser handshake uses. HYPOTHESIS, not established: this is the DLCM side of the scan-tool 'Immobilizer Password Learn' procedure described in the factory manual's RCU immobiliser-functionality topic (internal-only), which pairs a password into both the RCU and the DLCM.";
CM_ BO_ 786 "DLCM torque and torque-limit broadcast, 10 ms. NOT an ESC message -- it is TX record 10 in the DLCM's own transmit table and FUN_80080C14 writes all eight bytes. All three fields use the 0x212 encoding, 0.25 Nm/count with zero at 2000, written by FUN_80074780 from the 0xD00069Dx mirror block. TorqueFeedback (B0-B1) is duplicated bit-for-bit at B2-B3 in 197,193 of 197,193 frames; it tracks 0x1C0 Torque with r = 0.9994 and a least-squares slope of 0.24993 Nm/count with zero at 1999.5, median error 0.90 Nm, against 1.25 Nm for the 0x212 request -- consistent with achieved rather than requested torque, though the two references are themselves r = 0.99 to each other. M_MAX and M_MIN are the positive and regen torque limits: the 0x212 request lies inside them in 99.997 % of samples and sits exactly on M_MAX in 1.07 %, and M_MAX collapses from +299.75 Nm to +29.75 Nm whenever the brake switch is on (100.0 % of 90,230 brake-off frames against 97.2 % of 1,650 brake-on frames). Parity at B0 bit 5 over (B0 & 0x5F) ^ B1 holds in 197,193 of 197,193 frames. Supersedes the ESC wheel-speed and ESC-deceleration readings in projects/coda/README.md, notes/traction-control-analysis.md, notes/othercars-comparison.md and notes/driver-inputs.md.";
CM_ BO_ 1425 "DLCM -> RCU immobiliser verdict, event-driven (TX record 0, no period). Corpus-wide B0 takes exactly two values, 0xA0 (31 frames) and 0xB0 (12), which is what FUN_8007385E can produce: (flag != 1) * 0x10 + 0xA0. 0xA0 follows a completed 0x592/0x614 challenge-response; 0xB0 appears alone. Which value means pass is inferred from that ordering, not proved. See the factory manual's RCU immobiliser-functionality topic (internal-only).";
CM_ BO_ 1426 "DLCM -> RCU immobiliser challenge, event-driven (TX record 1). Eight bytes, all 36 observed payloads distinct. FUN_80073A8C generates it from a random source plus a flash constant at 0x80043F2D and publishes it immediately. Sent about 10 ms after the RCU's 0x603 step 0x20 and answered by 0x614 about 5 ms later.";
CM_ BO_ 1427 "Configured as an RX message, event-driven, and read by the firmware (signal 0x800F at 0x80080402, setting a flag at 0xD0007F87), but never observed: zero frames in 1,030 corpus captures. Part of the immobiliser message group; unused on this build.";
CM_ BO_ 1429 "Configured as a TX message but there is no publish call for it anywhere in the image, and it has never been observed: zero frames in 1,030 corpus captures. Dead configuration.";
CM_ BO_ 1539 "RCU -> DLCM immobiliser command, event-driven. Observed payloads: 02 FF 00 01 18 00 00 (237 frames, idle/status), 11 FF 00 00 18 00 00 (31, start) and 20 01 00 01 18 00 00 (33, request challenge), plus three rare variants differing only in B4. The full handshake is 0x603 step 0x02, then 0x11, then 0x20, then DLCM 0x592, then RCU 0x614, then DLCM 0x591, spanning about 30 ms. Sender attributed to the RCU on the service manual's description of RCU/DLCM authentication plus the fact that this group is D CAN only and never gateway-rebroadcast.";
CM_ BO_ 1556 "RCU -> DLCM immobiliser response to the 0x592 challenge, event-driven. Eight bytes, all observed payloads distinct. Receipt sets a flag at 0xD0007F85 which drives the DLCM's verdict state machine (FUN_80073F24); that machine latches a lockout after 4 failed attempts, matching the service manual's 'maximum 4 attempts, approximately one each 100 ms'.";

VAL_ 880 VehiclePowerState 0 "Off" 1 "Shutdown" 2 "Accessory" 3 "KeyOffTransition" 4 "IgnitionOn" 5 "Ready" 6 "PostCrank" 9 "Crank" ;
VAL_ 512 SubFrameID 0 "WheelSpeeds" 20 "WheelSpeeds_Degraded_0x14" 28 "ESC_Init_0x1C" 30 "ESC_Init_0x1E" 32 "TCEvent_0x20" ;
VAL_ 776 ParkRequest 0 "OFF" 1 "Park" 2 "UnPark" ;
VAL_ 1048 PRND 80 "P" 82 "R" 78 "N" 68 "D" ;
VAL_ 1372 parkLockState 0 "OFF" 1 "Park" 2 "Parked" 3 "ParkStalled" 4 "Unparking" 5 "Unparked" 6 "UnparkStalled" ;
CM_ BO_ 768 "ESC torque-limits message on D CAN (DLCM spec 8.3.1: MMIN_ESP, M_ESP, MMAX_ESP_REGEN_TQ_REQ, MPAR_ESP, MTOG_ESP), 50 Hz, B0 always 0x00. **A DIFFERENT message shares this ID on C CAN** -- native BMS diagnostic-port traffic, multiplexed 8 ways with B0 in {0,5,10,...,35}. Identify the bus by content, never by channel number: the numbering swaps between captures. Merging the two fakes both the rate (~59 Hz) and the structure. B4-B5 = a live 16-bit torque-limit value that begins ramping ~2.5 s before 0x212 responds (ESC-initiated TC). B1 toggles 0x00/0x80 at 50:50, MTOG_ESP candidate. B0/B2/B3 constant. See notes/traction-control-analysis.md Phase 2b and notes/yaw-rate-signal.md. FIRMWARE CROSS-CHECK 2026-09-24: Layout read out of the DLCM firmware (TriCore image coda_dlcm_prog.bin): every received payload is fetched into a per-message RAM buffer and read only through the accessor band 0x800803FA-0x80080B4A, so the masks there are the module's own view of the field. See notes/dlcm/coda-dlcm-decompile-notes.md and notes/dlcm/artifacts/dlcm_signal_map.py. FUN_80080572 reads B4 masked 0x1F with B5, which is exactly MMAX_ESP_REGEN_TQ_REQ as declared here (36|13@0), so the 13-bit reading is confirmed against the module. Four further bits are consumed but not declared: B4 bit 7 (toggles 50 %, the bit that must be masked off when reading B4-B5 as a word), B1 bit 7 (toggles 50 %, the MTOG_ESP candidate -- the DLCM really does read it), and B4 bits 5 and 6, both zero in all 98,624 frames observed. **CORRECTION 2026-10-03: B4 BIT 6 IS NOT ALWAYS ZERO AND IT IS NOT A SPARE -- IT IS THE ARMING GATE FOR THE B4-B5 LIMIT, now declared as ESP_TractiveTqLimit_Armed.** It is set in 46 of 315,555 d_can frames (0.0146 %), which is why a 98,624-frame population missed it; absence in a sample of a 1-in-7000 event is not evidence. B4 bit 7 remains an alternate-frame toggle, measured at 49.9998 % over the same 315,555 frames, and B4 bit 5 is still zero in all of them (role unknown; accessor FUN_80080560 reads it to a0-0x27bd and it feeds DTC 0x6e logic). B2 bits 5, 6 and 7 are zero in all 315,555 frames -- the braking-side field has NO arming bit, which matches FUN_800771FA, whose first gate has no runtime flag. FUN_80080588 reads B2 masked 0x1F with B3 as a SECOND 13-bit field on the same encoding; it is constant 0x12C0 = 4800 = +700 Nm in every frame, so it never binds. **CORRECTION 2026-10-03: BOTH OF THOSE 'NEVER BINDS' CLAIMS ARE FALSE, AND B2-B3 IS NOT CONSTANT.** The two 13-bit fields are a MATCHED PAIR OF TORQUE LIMITS, one per sign, and both bind. FUN_8006F05A scales both identically as raw*5>>1-5000 (= raw*2.5-5000, the scale/offset declared here, now confirmed from code) and stores them at 0xD0006824 (B2-B3) and 0xD0006826 (B4-B5). Each is read in exactly ONE place, adjacent instructions in FUN_800771FA (<- FUN_8007689C <- FUN_8007C33A, the torque task), which applies each as min(value, max(esc_limit, 0)) gated by CAL 0xA0021715 (B2-B3) and 0xA0021716 (B4-B5), both = 1 in stock. The clamped values are MAGNITUDES: FUN_800768D6 negates one and passes the other, selected by a direction flag built from DAT_d00050ab and signed speed 0xD0005114 against CAL +/-140 with debounce 20. MOVING FORWARD, B2-B3 is the REGEN limit and B4-B5 the DRIVE limit; they SWAP in reverse. Evidence: B2-B3 reached raw 2000 = 0.00 Nm for 46 frames on 2026-10-02 (coda_20261002_175334 t=424) and all 156 Nm of regen went with it, while in two other sessions it is the ONLY value in 49,527 and 37,783 frames; and B4-B5 fell to 1678 internal = +167.8 Nm against a +253.0 Nm request during a 369-count wheel-slip event in codadriveslowturnonwithdefroster2.log t=586, with delivered torque following it to 166.5 Nm. THE NAMING CONFLICT IS RESOLVED (2026-10-03): B4-B5 was renamed ESP_TractiveTqLimit and B2-B3 declared as ESP_BrakingTqLimit, both named for what they bound relative to TRAVEL DIRECTION. The firmware agrees that B4-B5 is the drive-side limit, so the name is now a description rather than a conflict. See notes/dlcm/esp-torque-intervention.md. The DLCM does not read YawRate (B6-B7).";
CM_ SG_ 768 ESP_TractiveTqLimit_Armed "B4 bit 6. ADDED 2026-10-03. The runtime arming gate for ESP_TractiveTqLimit: when this is 0 that limit is inert and idles at a value equal to the 0x212 torque request, and when it is 1 the limit binds and delivered torque follows it. Position and role are the firmware's own: accessor FUN_8008054E returns (B4 & 0x40) >> 6, FUN_8006F05A copies it to 0xD0006844, and FUN_800771FA consults it as the first term of the gate on the tractive application a0-0x2540 = min(a0-0x253a, max(0xD0006826, 0)). The braking-side field has no equivalent bit -- its gate is CAL 0xA0021715 and fault flags only -- and that single asymmetry is why the two limits behave so differently despite identical scaling and both calibrations being enabled (0xA0021715 = 0xA0021716 = 1 in stock). Measured: set in 46 of 315,555 d_can frames (0.0146 %). Gating on it yields 34 episodes across 29 of 396 sessions swept, 0.02-0.86 s, versus whole-drive garbage from any threshold on the limit value itself. One episode of the 34 arms WITHOUT binding (coda_20260721_215506 t=176.79, limit 217.00 above a request of 194.75), so a set bit means the limit is live, not that torque was removed. Prior comments on this message recorded B4 bits 5 and 6 as always zero over 98,624 frames; that population was simply too small for a 1-in-7000 event. See notes/dlcm/esp-torque-intervention.md.";
CM_ SG_ 768 ESP_TractiveTqLimit "RENAMED 2026-10-03 from MMAX_ESP_REGEN_TQ_REQ. The old name is from the DLCM spec list (8.3.1) and sits on the field that clamps TRACTIVE torque, not regen; named here for what it bounds relative to TRAVEL DIRECTION, because the pair swaps roles in reverse and any sign-based name is wrong in one gear. B4-B5, 13-bit big-endian, the same torque encoding as 0x212 and 0x312: internal = (raw - 2000) / 0.4, i.e. 2.5 internal counts per raw count, zero at raw 2000. Units are DLCM internal torque counts at ~0.096 Nm each. CONFIRMED 2026-09-24 on the D CAN bus (n=15001, exactly 50.0 Hz, DLC 8, B0 = 0x00 in every frame). **MASK WITH 0x1FFF.** B4 bit 7 toggles on exactly alternate frames (50.0 percent measured); reading B4-B5 as a plain 16-bit value returns hundreds of spurious values in two interleaved families 32768 apart, which is what left this signal uncharacterised since the traction-control work. The separate B1 0x00/0x80 toggle recorded in this message comment is ALSO real (49.5 percent measured) -- there are two toggling bits and the B1 note is not superseded. B2-B3 are constant 0x12C0. ~~IT IS A MIRROR OF DELIVERED TORQUE, NOT AN ACTIVE LIMIT~~ -- **WITHDRAWN 2026-10-03: IT DOES BIND.** The withdrawn reading was: its floor tracks whatever the accelerator map requests (-690 internal when the coast row asked -690, -1570 when it asked -1562), sitting slightly deeper than delivered torque, established across three drives. The error was that it IDLES AT THE VALUE IT IS LIMITING -- 2870 against a request of 2872 one sample earlier -- so 'mirror' and 'limit' are the same data until the moment it departs, and in those three drives it never departed. Measured departure: codadriveslowturnonwithdefroster2.log t=586, during a 369-count front-wheel-slip event, it falls to 1678 internal = +167.8 Nm against a +253.0 Nm request and delivered torque follows it down to 166.5 Nm. It is the DRIVE-side limit in forward motion; B2-B3 is the regen-side one, so the name is a description and the former naming conflict is closed. **THE DISCRIMINATOR IS ESP_TractiveTqLimit_Armed (B4 bit 6), FOUND 2026-10-03 -- READ THAT SIGNAL BEFORE USING THIS ONE.** With it CLEAR, which is 99.985 % of frames, this field idles at a value equal to the 0x212 torque request (MAE 0.28-0.39 Nm, median residual 0.000, p99 0.750 Nm = one LSB, measured on raw frames over six sessions) and FUN_800771FA's min() is a no-op. With it SET, the field departs BELOW the request by 6.75-88.75 Nm and delivered torque follows the limit, not the request. Corpus-wide, gated on the arming bit: 34 episodes across 29 sessions of 396 swept, durations p50 0.12 s and max 0.86 s, limit floors 148-223 internal-Nm against a ~300 Nm ceiling. **CONSEQUENCE FOR ANALYSIS: no threshold on this field's VALUE can detect an intervention, because its idle value is not a sentinel -- it is another live signal.** An absolute threshold returns whole drives (285 'episodes' corpus-wide) and a request-minus-limit gap detector compares the request against a copy of itself. Also superseded: 'internal torque counts at ~0.096 Nm each' is 0.1 Nm/count exactly, and 'B2-B3 are constant 0x12C0' is false. See notes/dlcm/esp-torque-intervention.md.";
CM_ SG_ 768 ESP_BrakingTqLimit "B2-B3, 13-bit big-endian, mask 0x1F on B2. ADDED 2026-10-03. The ESC limit on torque OPPOSING travel -- in forward motion the REGEN limit; it swaps with ESP_TractiveTqLimit in reverse, because FUN_800768D6 negates one of the two clamp outputs and passes the other according to a direction flag built from DAT_d00050ab and signed speed 0xD0005114 against CAL +/-140 with debounce 20. Position and width are the firmware's own: accessor FUN_80080588 returns (B2 & 0x1F) << 8 | B3. Scale confirmed from code, not assumed: FUN_8006F05A computes raw*5>>1-5000 = raw*2.5-5000 for this field and for B4-B5 alike, giving DLCM internal torque counts at 0.1 Nm each. Applied as min(magnitude, max(limit, 0)) in FUN_800771FA, gated by CAL 0xA0021715 (= 1 in stock). IDLES AT raw 4800 = 7000 internal = +700 Nm, far above the 300 Nm motor ceiling, so it is inert by magnitude and reads as a constant: it is the ONLY value in 49,527 frames of coda_20261002_195747 and 37,783 of coda_20260904_181915, and was recorded as 'constant 0x12C0, never binds' on that basis. It DOES bind: in coda_20261002_175334 at t=424 it ramps to raw 2000 = 0.00 Nm, holds for 46 frames / 0.9 s, and all 156 Nm of commanded regen goes with it -- 40 ms after a driven-front-wheel slip of 109 counts and coincident with ABS_BrakeEvent on 0x208. Recovery is ramped by the ESC in 4-count steps over ~8 s, not snapped. The DLCM keeps publishing the pre-clamp request on 0x212 throughout, and the reason is now traced: FUN_80075CF8 writes the rate-limited torque to TWO sinks on adjacent lines -- 0xD0006A5A unclamped, which reaches 0x212, and 0xD0006A4E clamped to FUN_800768D6's ESC-applied pair at 0xD0006AA0/0xD0006AA2. 0x212 is fed from the sink taken BEFORE the clamp, by construction. The applied result IS visible on D CAN as 0x312 TorqueFeedback, which collapses in 0.16-0.21 s at all five events while the published request takes 1.5-2 s, so no M CAN access is needed to observe an intervention. See notes/dlcm/esp-torque-intervention.md.";
CM_ SG_ 520 ABS_BrakeEvent "B0 bit 6. ADDED 2026-10-03. The ABS brake-event line from the ESC. Name is the DLCM's own: accessor FUN_8008060E (a0-0x1060 & 0x40 >> 6) feeds FUN_8006ED3C, which runs a rationality counter against CAL 0xA00212BE = 6000 into DEM event 124 = U2111 'Invalid Anti Lock Braking System Brake Event'. The adjacent bit via FUN_800805EE feeds event 123 = U2110 'Invalid Anti-Lock Braking System Lamp Request'. RARE: asserts for 98 frames / 0.97 s in coda_20261002_175334 at t=424.02 -- 40 ms after a driven-wheel slip and 40 ms before a full regen cut -- and is 0 across 650,000+ frames of six other sessions, including the 2026-03 defroster drive which contains 82 samples of wheel slip up to 369 counts. So it is specific to braking events, not to slip. Its single consumer in the image is FUN_800764F6, which forces that function's output to zero when this bit and the commanded brake-lamp state 0xD0006831 are both set. See notes/dlcm/esp-torque-intervention.md.";
CM_ SG_ 768 YawRate "ESC yaw-rate gyro, confirmed 2026-09-21. B6-B7 big-endian, ZERO = 32792 raw (identical across four logs spanning 2026-02..08). Positive = left turn (raw rises as the right wheels outrun the left). 0xFFFF is an invalid sentinel, ~0.09 percent of frames, mostly at standstill -- discard it. IT IS A SENSOR, not a value computed from wheel speed: at standstill it sits at its zero with sd ~12-23 counts of its own noise, whereas anything derived from wheel speeds would be identically zero. Correlation against a yaw reference built from the rear wheel-speed difference rises from 0.88 raw to 0.994 at 0.3 s smoothing and 0.998 at 1.2 s, so the residual is that reference's quantisation noise, not a different quantity. SCALE IS APPROXIMATE: 0.00944 deg/s per count measured across four logs with a 2.0 percent spread, using the owner-supplied 59 in rear track; it also inherits the wheel-speed constant's uncertainty. 0.01 is 5.6 percent away and NOT supported. Note the earlier MPAR_ESP parity hypothesis for B7 is DISPROVED -- consecutive |delta(B6-B7)| has mean 11 and median 8, where a checksum byte would give ~85 uniformly, and including B7 RAISES the smoothed correlation. See notes/yaw-rate-signal.md.";
VAL_ 1536 TPMS_TelltaleFault 0 "OFF" 1 "FAULT_LAMP_ON" ;
